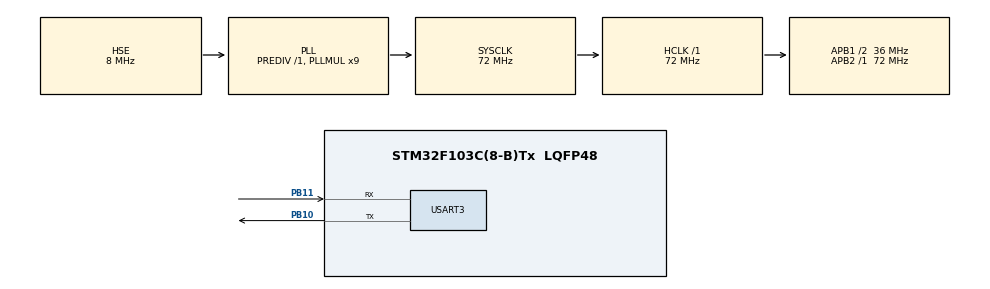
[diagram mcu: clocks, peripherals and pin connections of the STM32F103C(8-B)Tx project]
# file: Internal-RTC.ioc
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Mcu.Family=STM32F1
Mcu.Name=STM32F103C(8-B)Tx
Mcu.Package=LQFP48
NVIC.PriorityGroup=NVIC_PRIORITYGROUP_4
PA13.Mode=Serial_Wire
PA13.Signal=SYS_JTMS-SWDIO
PA14.Mode=Serial_Wire
PA14.Signal=SYS_JTCK-SWCLK
PB10.Mode=Asynchronous
PB10.Signal=USART3_TX
PB11.Mode=Asynchronous
PB11.Signal=USART3_RX
PC14-OSC32_IN.Mode=LSE-External-Oscillator
PC14-OSC32_IN.Signal=RCC_OSC32_IN
PC15-OSC32_OUT.Mode=LSE-External-Oscillator
PC15-OSC32_OUT.Signal=RCC_OSC32_OUT
PD0-OSC_IN.Mode=HSE-External-Oscillator
PD0-OSC_IN.Signal=RCC_OSC_IN
PD1-OSC_OUT.Mode=HSE-External-Oscillator
PD1-OSC_OUT.Signal=RCC_OSC_OUT
ProjectManager.HeapSize=0x200
ProjectManager.StackSize=0x400
ProjectManager.TargetToolchain=STM32CubeIDE
RCC.AHBFreq_Value=72000000
RCC.APB1CLKDivider=RCC_HCLK_DIV2
RCC.APB1Freq_Value=36000000
RCC.APB1TimFreq_Value=72000000
RCC.APB2Freq_Value=72000000
RCC.APB2TimFreq_Value=72000000
RCC.EnbaleCSS=true
RCC.HCLKFreq_Value=72000000
RCC.PLLMUL=RCC_PLL_MUL9
RCC.PLLSourceVirtual=RCC_PLLSOURCE_HSE
RCC.RTCClockSelection=RCC_RTCCLKSOURCE_LSE
RCC.SYSCLKFreq_VALUE=72000000
RCC.SYSCLKSource=RCC_SYSCLKSOURCE_PLLCLK
RCC.USBFreq_Value=72000000
RTC.Date=10
RTC.Format=RTC_FORMAT_BIN
RTC.Minutes=55
RTC.Month=RTC_MONTH_FEBRUARY
RTC.WeekDay=RTC_WEEKDAY_WEDNESDAY
RTC.Year=21
USART3.VirtualMode=VM_ASYNC
VP_RTC_No_RTC_Output.Mode=RTC_OUT_NO
VP_RTC_VS_RTC_Activate.Mode=RTC_Enabled
VP_RTC_VS_RTC_Calendar.Mode=RTC_Calendar
board=custom

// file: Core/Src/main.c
/* USER CODE BEGIN Header */
/**
  ******************************************************************************
  * @file           : main.c
  * @brief          : Main program body
  ******************************************************************************
  * @attention
  *
  * <h2><center>&copy; Copyright (c) 2021 STMicroelectronics.
  * All rights reserved.</center></h2>
  *
  * This software component is licensed by ST under BSD 3-Clause license,
  * the "License"; You may not use this file except in compliance with the
  * License. You may obtain a copy of the License at:
  *                        opensource.org/licenses/BSD-3-Clause
  *
  ******************************************************************************
  ******************************************************************************
  ******************************************************************************

  https://blog.avislab.com/stm32-rtc_ru/

  */

/* USER CODE END Header */
#include "main.h"
#include "rtc.h"
#include "usart.h"
#include "gpio.h"

/* USER CODE BEGIN Includes */

#include "internalRTC.h"
/* USER CODE END Includes */

/* USER CODE BEGIN PV */
RTC_TimeTypeDef sTime = {0};
RTC_DateTypeDef DateToUpdate = {0};

/* USER CODE END PV */

void SystemClock_Config(void);

/* USER CODE BEGIN 0 */

static uint32_t RTC_ReadTimeCounter(RTC_HandleTypeDef *hrtc)
{
  uint16_t high1 = 0U, high2 = 0U, low = 0U;
  uint32_t timecounter = 0U;

  high1 = READ_REG(hrtc->Instance->CNTH & RTC_CNTH_RTC_CNT);
  low   = READ_REG(hrtc->Instance->CNTL & RTC_CNTL_RTC_CNT);
  high2 = READ_REG(hrtc->Instance->CNTH & RTC_CNTH_RTC_CNT);

  if (high1 != high2)
  {
    /* In this case the counter roll over during reading of CNTL and CNTH registers,
       read again CNTL register then return the counter value */
    timecounter = (((uint32_t) high2 << 16U) | READ_REG(hrtc->Instance->CNTL & RTC_CNTL_RTC_CNT));
  }
  else
  {
    /* No counter roll over during reading of CNTL and CNTH registers, counter
       value is equal to first value of CNTL and CNTH */
    timecounter = (((uint32_t) high1 << 16U) | low);
  }

  return timecounter;
}

/* USER CODE END 0 */

int main(void)
{
  /* USER CODE BEGIN 1 */
	char buffer[80];
	uint32_t RTC_Counter = 0;
	RTC_DateTimeTypeDef	RTC_DateTime;
  /* USER CODE END 1 */

  /* MCU Configuration--------------------------------------------------------*/

  /* Reset of all peripherals, Initializes the Flash interface and the Systick. */
  HAL_Init();

  /* Configure the system clock */
  SystemClock_Config();

  /* Initialize all configured peripherals */
  MX_GPIO_Init();
  MX_RTC_Init();
  MX_USART3_UART_Init();

  /* Infinite loop */
  /* USER CODE BEGIN WHILE */
  while (1)
  {
      HAL_RTC_GetTime(&hrtc, &sTime, RTC_FORMAT_BIN); // RTC_FORMAT_BIN , RTC_FORMAT_BCD
      snprintf(buffer, 80, "Time %d:%d:%d\n", sTime.Hours, sTime.Minutes, sTime.Seconds);
      HAL_UART_Transmit(&huart3, (uint8_t*)buffer, strlen(buffer), 1000);

      HAL_RTC_GetDate(&hrtc, &DateToUpdate, RTC_FORMAT_BIN);
      snprintf(buffer, 80, "Date %d-%d-20%d\n", DateToUpdate.Date, DateToUpdate.Month, DateToUpdate.Year);
      HAL_UART_Transmit(&huart3, (uint8_t*)buffer, strlen(buffer), 1000);

      uint32_t raw_val = RTC_ReadTimeCounter(&hrtc);
      snprintf(buffer, 80, "%lu\n", raw_val);
			 HAL_UART_Transmit(&huart3, (uint8_t*)buffer, strlen(buffer), 1000);

      HAL_Delay(1000);

/*
	  	  RTC_Counter = RTC_GetCounter();
	  		sprintf(buffer, "\r\n\r\nCOUNTER: %d\r\n", (int)RTC_Counter);
	  		HAL_UART_Transmit(&huart3, (uint8_t*)buffer, strlen(buffer), 100);

	  		RTC_GetDateTime(RTC_Counter, &RTC_DateTime);
	  		snprintf(buffer, 80, "%02d.%02d.%04d  %02d:%02d:%02d\n",
	  			RTC_DateTime.RTC_Date, RTC_DateTime.RTC_Month, RTC_DateTime.RTC_Year,
	  			RTC_DateTime.RTC_Hours, RTC_DateTime.RTC_Minutes, RTC_DateTime.RTC_Seconds);

	  		HAL_UART_Transmit(&huart3, (uint8_t*)buffer, strlen(buffer), 100);

	  		// Функция генерирует в буфере дату собственного формата
	  		RTC_GetMyFormat(&RTC_DateTime, buffer);
	  		HAL_UART_Transmit(&huart3, (uint8_t*)buffer, strlen(buffer), 100);
*/
	  		// delay

	  	 //while (RTC_Counter == RTC_GetCounter()) {
      //
      //  		}
    /* USER CODE END WHILE */

  }
}

void SystemClock_Config(void)
{
  RCC_OscInitTypeDef RCC_OscInitStruct = {0};
  RCC_ClkInitTypeDef RCC_ClkInitStruct = {0};
  RCC_PeriphCLKInitTypeDef PeriphClkInit = {0};

  /** Initializes the RCC Oscillators according to the specified parameters
  * in the RCC_OscInitTypeDef structure.
  */
  RCC_OscInitStruct.OscillatorType = RCC_OSCILLATORTYPE_HSE|RCC_OSCILLATORTYPE_LSE;
  RCC_OscInitStruct.HSEState = RCC_HSE_ON;
  RCC_OscInitStruct.HSEPredivValue = RCC_HSE_PREDIV_DIV1;
  RCC_OscInitStruct.LSEState = RCC_LSE_ON;
  RCC_OscInitStruct.HSIState = RCC_HSI_ON;
  RCC_OscInitStruct.PLL.PLLState = RCC_PLL_ON;
  RCC_OscInitStruct.PLL.PLLSource = RCC_PLLSOURCE_HSE;
  RCC_OscInitStruct.PLL.PLLMUL = RCC_PLL_MUL9;
  if (HAL_RCC_OscConfig(&RCC_OscInitStruct) != HAL_OK)
  {
    Error_Handler();
  }
  /** Initializes the CPU, AHB and APB buses clocks
  */
  RCC_ClkInitStruct.ClockType = RCC_CLOCKTYPE_HCLK|RCC_CLOCKTYPE_SYSCLK
                              |RCC_CLOCKTYPE_PCLK1|RCC_CLOCKTYPE_PCLK2;
  RCC_ClkInitStruct.SYSCLKSource = RCC_SYSCLKSOURCE_PLLCLK;
  RCC_ClkInitStruct.AHBCLKDivider = RCC_SYSCLK_DIV1;
  RCC_ClkInitStruct.APB1CLKDivider = RCC_HCLK_DIV2;
  RCC_ClkInitStruct.APB2CLKDivider = RCC_HCLK_DIV1;

  if (HAL_RCC_ClockConfig(&RCC_ClkInitStruct, FLASH_LATENCY_2) != HAL_OK)
  {
    Error_Handler();
  }
  PeriphClkInit.PeriphClockSelection = RCC_PERIPHCLK_RTC;
  PeriphClkInit.RTCClockSelection = RCC_RTCCLKSOURCE_LSE;
  if (HAL_RCCEx_PeriphCLKConfig(&PeriphClkInit) != HAL_OK)
  {
    Error_Handler();
  }
  /** Enables the Clock Security System
  */
  HAL_RCC_EnableCSS();
}

void Error_Handler(void)
{
  __disable_irq();
  while (1)
  {
  }
}

/************************ (C) COPYRIGHT STMicroelectronics *****END OF FILE****/
